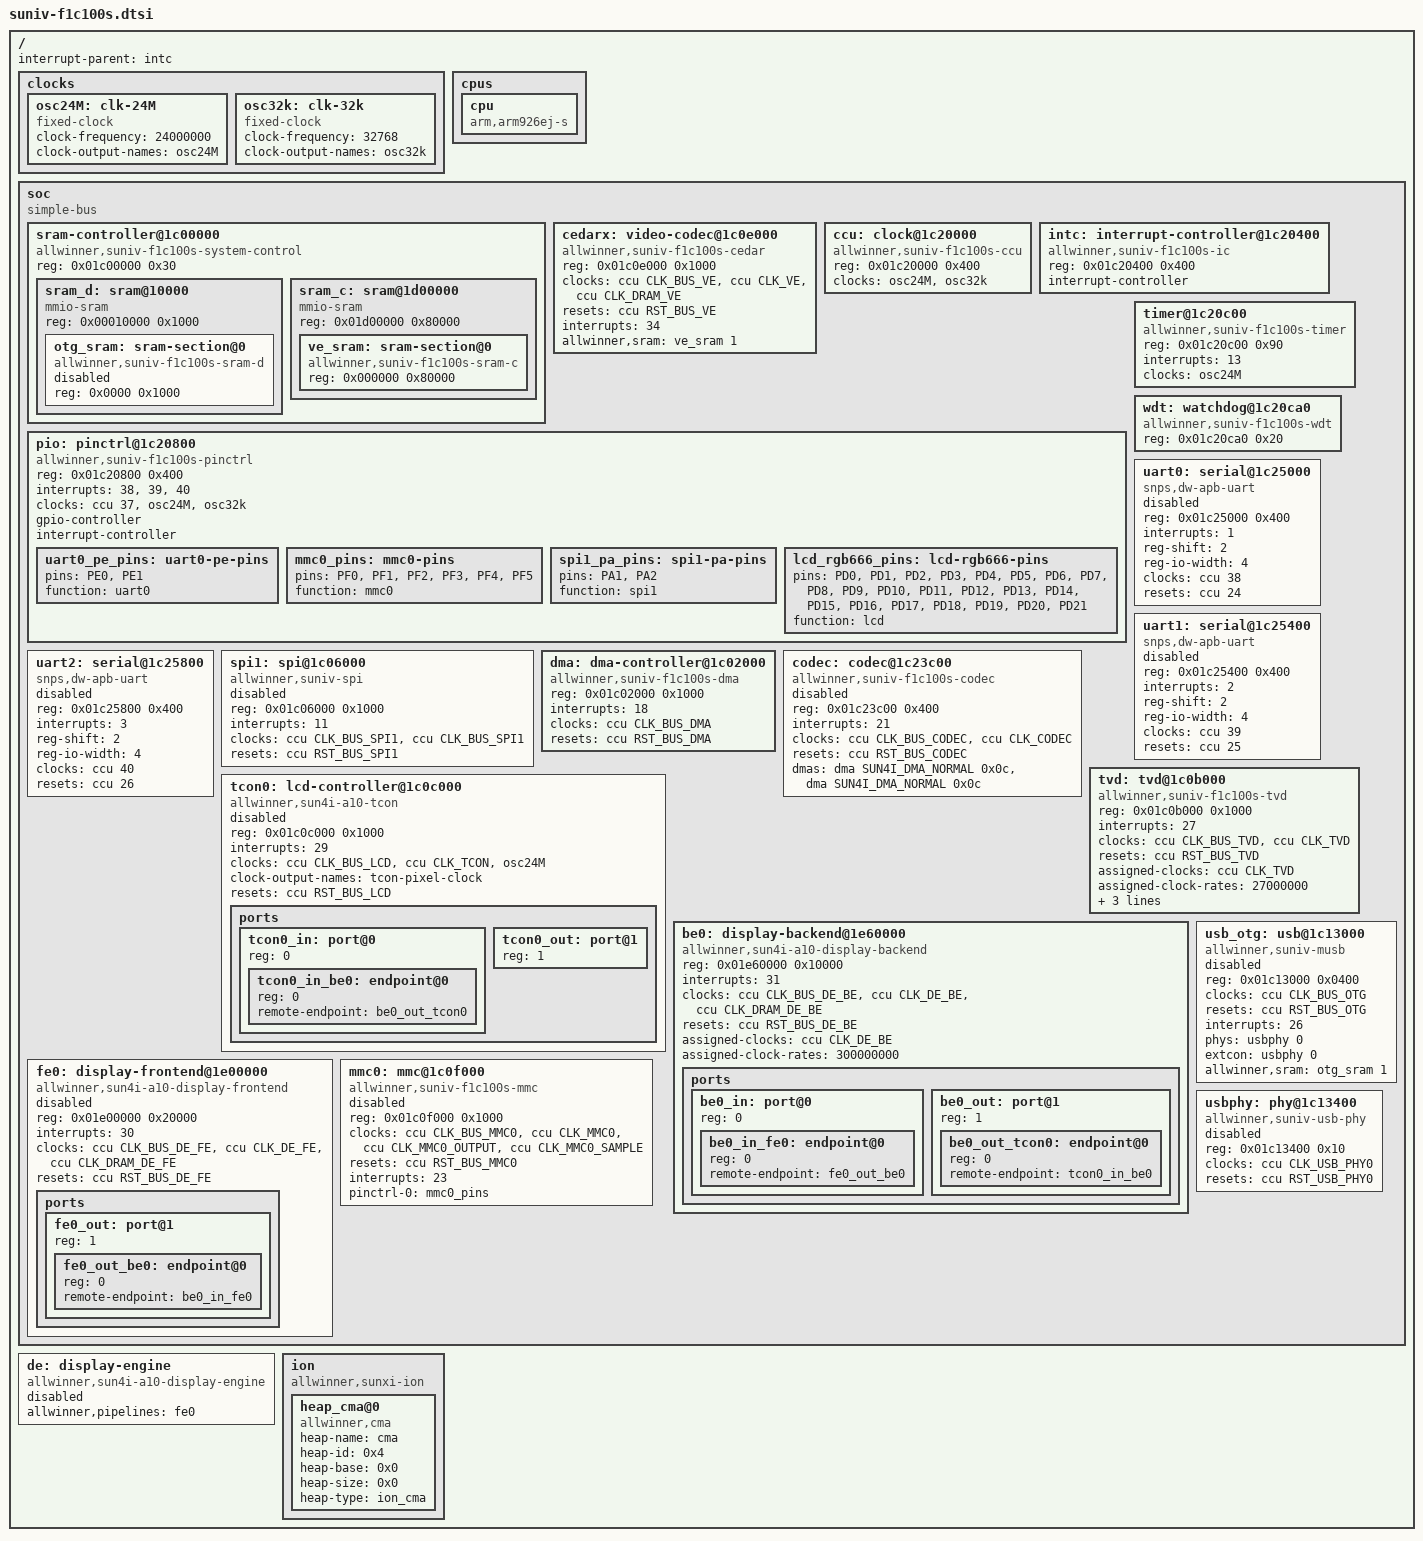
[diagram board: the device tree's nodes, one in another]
// SPDX-License-Identifier: (GPL-2.0+ OR X11)
/*
 * Copyright 2018 Icenowy Zheng <icenowy@aosc.io>
 * Copyright 2018 Mesih Kilinc <mesihkilinc@gmail.com>
 */
#include <dt-bindings/clock/suniv-ccu-f1c100s.h>
#include <dt-bindings/reset/suniv-ccu-f1c100s.h>
#include <dt-bindings/dma/sun4i-a10.h>


/ {
	#address-cells = <1>;
	#size-cells = <1>;
	interrupt-parent = <&intc>;

	clocks {
		osc24M: clk-24M {
			#clock-cells = <0>;
			compatible = "fixed-clock";
			clock-frequency = <24000000>;
			clock-output-names = "osc24M";
		};

		osc32k: clk-32k {
			#clock-cells = <0>;
			compatible = "fixed-clock";
			clock-frequency = <32768>;
			clock-output-names = "osc32k";
		};
	};

	cpus {
		cpu {
			compatible = "arm,arm926ej-s";
			device_type = "cpu";
		};
	};

	soc {
		compatible = "simple-bus";
		#address-cells = <1>;
		#size-cells = <1>;
		ranges;

  sram-controller@1c00000 {
      compatible = "allwinner,suniv-f1c100s-system-control",
                   "allwinner,sun4i-a10-system-control";
      reg = <0x01c00000 0x30>;
      #address-cells = <1>;
      #size-cells = <1>;
      ranges;

      sram_d: sram@10000 {
          compatible = "mmio-sram";
          reg = <0x00010000 0x1000>;
          #address-cells = <1>;
          #size-cells = <1>;
          ranges = <0 0x00010000 0x1000>;

          otg_sram: sram-section@0 {
              compatible = "allwinner,suniv-f1c100s-sram-d",
                           "allwinner,sun4i-a10-sram-d";
              reg = <0x0000 0x1000>;
              status = "disabled";
          };
      };

      sram_c: sram@1d00000 {
          compatible = "mmio-sram";
          reg = <0x01d00000 0x80000>;
          #address-cells = <1>;
          #size-cells = <1>;
          ranges = <0 0x01d00000 0x80000>;

          ve_sram: sram-section@0 {
              compatible = "allwinner,suniv-f1c100s-sram-c",
                           "allwinner,sun4i-a10-sram-c1";
              reg = <0x000000 0x80000>;
          };
      };
  };
  cedarx: video-codec@1c0e000 {
      compatible = "allwinner,suniv-f1c100s-cedar";
      reg = <0x01c0e000 0x1000>;
      clocks = <&ccu CLK_BUS_VE>, <&ccu CLK_VE>, <&ccu CLK_DRAM_VE>;
      clock-names = "ahb", "mod", "ram";
      resets = <&ccu RST_BUS_VE>;
      interrupts = <34>;
      allwinner,sram = <&ve_sram 1>;
      status = "okay";
  };

		ccu: clock@1c20000 {
			compatible = "allwinner,suniv-f1c100s-ccu";
			reg = <0x01c20000 0x400>;
			clocks = <&osc24M>, <&osc32k>;
			clock-names = "hosc", "losc";
			#clock-cells = <1>;
			#reset-cells = <1>;
		};

		intc: interrupt-controller@1c20400 {
			compatible = "allwinner,suniv-f1c100s-ic";
			reg = <0x01c20400 0x400>;
			interrupt-controller;
			#interrupt-cells = <1>;
		};

		pio: pinctrl@1c20800 {
			compatible = "allwinner,suniv-f1c100s-pinctrl";
			reg = <0x01c20800 0x400>;
			interrupts = <38>, <39>, <40>;
			clocks = <&ccu 37>, <&osc24M>, <&osc32k>;
			clock-names = "apb", "hosc", "losc";
			gpio-controller;
			interrupt-controller;
			#interrupt-cells = <3>;
			#gpio-cells = <3>;

			uart0_pe_pins: uart0-pe-pins {
				pins = "PE0", "PE1";
				function = "uart0";
			};
			mmc0_pins: mmc0-pins {
                		pins = "PF0", "PF1", "PF2", "PF3", "PF4", "PF5";
                		function = "mmc0";
            		};
spi1_pa_pins: spi1-pa-pins {
pins = "PA1", "PA2";
        function = "spi1";
            };
lcd_rgb666_pins: lcd-rgb666-pins {  //分号前是给节点起的别名，分号后是节点的名称。首先是申请RGB驱动的引脚
				pins = "PD0", "PD1", "PD2", "PD3", "PD4",
				       "PD5", "PD6", "PD7", "PD8", "PD9",
				       "PD10", "PD11", "PD12", "PD13", "PD14",
				       "PD15", "PD16", "PD17", "PD18", "PD19",
				       "PD20", "PD21";
				function = "lcd";
			};

		};

		timer@1c20c00 {
			compatible = "allwinner,suniv-f1c100s-timer";
			reg = <0x01c20c00 0x90>;
			interrupts = <13>;
			clocks = <&osc24M>;
		};

		wdt: watchdog@1c20ca0 {
			compatible = "allwinner,suniv-f1c100s-wdt",
				     "allwinner,sun4i-a10-wdt";
			reg = <0x01c20ca0 0x20>;
		};

		uart0: serial@1c25000 {
			compatible = "snps,dw-apb-uart";
			reg = <0x01c25000 0x400>;
			interrupts = <1>;
			reg-shift = <2>;
			reg-io-width = <4>;
			clocks = <&ccu 38>;
			resets = <&ccu 24>;
			status = "disabled";
		};

		uart1: serial@1c25400 {
			compatible = "snps,dw-apb-uart";
			reg = <0x01c25400 0x400>;
			interrupts = <2>;
			reg-shift = <2>;
			reg-io-width = <4>;
			clocks = <&ccu 39>;
			resets = <&ccu 25>;
			status = "disabled";
		};

		uart2: serial@1c25800 {
			compatible = "snps,dw-apb-uart";
			reg = <0x01c25800 0x400>;
			interrupts = <3>;
			reg-shift = <2>;
			reg-io-width = <4>;
			clocks = <&ccu 40>;
			resets = <&ccu 26>;
			status = "disabled";
		};
spi1: spi@1c06000 {
    compatible = "allwinner,suniv-spi",
                 "allwinner,sun8i-h3-spi";
    reg = <0x01c06000 0x1000>;
    interrupts = <11>;
    clocks = <&ccu CLK_BUS_SPI1>, <&ccu CLK_BUS_SPI1>;
    clock-names = "ahb", "mod";
    resets = <&ccu RST_BUS_SPI1>;
    status = "disabled";
    #address-cells = <1>;
    #size-cells = <0>;
};

dma: dma-controller@1c02000 {
    compatible = "allwinner,suniv-f1c100s-dma";
    reg = <0x01c02000 0x1000>;
    interrupts = <18>;
    clocks = <&ccu CLK_BUS_DMA>;
    resets = <&ccu RST_BUS_DMA>;
    #dma-cells = <2>;
};

codec: codec@1c23c00 {
    compatible = "allwinner,suniv-f1c100s-codec";
    reg = <0x01c23c00 0x400>;
    interrupts = <21>;
    clocks = <&ccu CLK_BUS_CODEC>,
         <&ccu CLK_CODEC>;
    clock-names = "apb", "codec";
    resets = <&ccu RST_BUS_CODEC>;
    dmas = <&dma SUN4I_DMA_NORMAL 0x0c>, 
         <&dma SUN4I_DMA_NORMAL 0x0c>;
    dma-names = "rx", "tx";
    status = "disabled";
};

  #include <dt-bindings/clock/suniv-ccu-f1c100s.h>
  #include <dt-bindings/reset/suniv-ccu-f1c100s.h>

  tvd: tvd@1c0b000 {
      compatible = "allwinner,suniv-f1c100s-tvd";
      reg = <0x01c0b000 0x1000>;
      interrupts = <27>;

      clocks = <&ccu CLK_BUS_TVD>,
               <&ccu CLK_TVD>;
      clock-names = "bus", "mod";

      resets = <&ccu RST_BUS_TVD>;
      reset-names = "bus";

      assigned-clocks = <&ccu CLK_TVD>;
      assigned-clock-rates = <27000000>;

      allwinner,input-channel = <0>;
      allwinner,default-standard = "ntsc";
      allwinner,blue-screen-mode = <2>;
      /* allwinner,auto-detect-standard; */

      status = "okay";
  };


tcon0: lcd-controller@1c0c000 {  //添加显示驱动的节点，即RGB驱动，@后面是设备的物理地址。
			compatible = "allwinner,sun4i-a10-tcon";  //linux5.7.1内，已经没有f1c200s的相关支持，但是实测使用a10型号的驱动依然可用
			reg = <0x01c0c000 0x1000>;  //寄存器地址
			interrupts = <29>;  //中断号，是根据f1c200s手册查询得到的
			clocks = <&ccu CLK_BUS_LCD>,  //这里引用了外部宏定义，所以要添加对应的头文件，默认已经添加过了
				 <&ccu CLK_TCON>,
				 <&osc24M>;	/* Still unknown */
			clock-names = "ahb",
				      "tcon-ch0",
				      "tcon-ch1";
			clock-output-names = "tcon-pixel-clock";
			resets = <&ccu RST_BUS_LCD>;  //指定复位单元
			reset-names = "lcd";  //复位单元名称？
			status = "disabled";  //先禁用设备

			ports {  //port是管道，或者说端口，设备间的数据通过管道传输。
				#address-cells = <1>;  //设置子节点的地址占用大小
				#size-cells = <0>;  //设置子节点寄存器尺寸描述占用大小

				tcon0_in: port@0 {  //port管道端口0是输入口
					#address-cells = <1>;
					#size-cells = <0>;
					reg = <0>;

					tcon0_in_be0: endpoint@0 {  //port管道端口0的对端口为be0_out_tcon0
						reg = <0>;
						remote-endpoint = <&be0_out_tcon0>;
					};
				};

				tcon0_out: port@1 {  //port管道端口1是输出口
					#address-cells = <1>;
					#size-cells = <0>;
					reg = <1>;
				};
			};
		};
		be0: display-backend@1e60000 {  //be0是显示后端处理，显示后端处理主要针对图片叠加
			compatible = "allwinner,sun4i-a10-display-backend";
			reg = <0x01e60000 0x10000>;
			reg-names = "be";
			interrupts = <31>;
			clocks = <&ccu CLK_BUS_DE_BE>, <&ccu CLK_DE_BE>,
				 <&ccu CLK_DRAM_DE_BE>;
			clock-names = "ahb", "mod",
				      "ram";
			resets = <&ccu RST_BUS_DE_BE>;
			reset-names = "be";
			assigned-clocks = <&ccu CLK_DE_BE>;
			assigned-clock-rates = <300000000>;

			ports {  //be0也是拥有两个端口
				#address-cells = <1>;
				#size-cells = <0>;

				be0_in: port@0 {  //be0管道端口0的对端是fe0_out_be0
					#address-cells = <1>;
					#size-cells = <0>;
					reg = <0>;

					be0_in_fe0: endpoint@0 {
						reg = <0>;
						remote-endpoint = <&fe0_out_be0>;
					};
				};

				be0_out: port@1 {  //be0管道端口1的对端是tcon0_in_be0
					#address-cells = <1>;
					#size-cells = <0>;
					reg = <1>;

					be0_out_tcon0: endpoint@0 {
						reg = <0>;
						remote-endpoint = <&tcon0_in_be0>;
					};
				};
			};
		};
		fe0: display-frontend@1e00000 {  //fe0是显示前端处理，显示前端主要针对图片的缩放。
			compatible = "allwinner,sun4i-a10-display-frontend";  //这里也是借用a10的驱动
			reg = <0x01e00000 0x20000>;
			interrupts = <30>;
			clocks = <&ccu CLK_BUS_DE_FE>, <&ccu CLK_DE_FE>,
				 <&ccu CLK_DRAM_DE_FE>;
			clock-names = "ahb", "mod",
				      "ram";
			resets = <&ccu RST_BUS_DE_FE>;
			status = "disabled";

			ports {
				#address-cells = <1>;
				#size-cells = <0>;

				fe0_out: port@1 {  //fe0管道端口1是输出口，其对端口为be0_in_fe0
					#address-cells = <1>;
					#size-cells = <0>;
					reg = <1>;

					fe0_out_be0: endpoint@0 {
						reg = <0>;
						remote-endpoint = <&be0_in_fe0>;
					};
				};
			};
		};

mmc0: mmc@1c0f000 {
            compatible = "allwinner,suniv-f1c100s-mmc",
                     "allwinner,sun7i-a20-mmc";
            reg = <0x01c0f000 0x1000>;
            clocks = <&ccu CLK_BUS_MMC0>,
                 <&ccu CLK_MMC0>,
                 <&ccu CLK_MMC0_OUTPUT>,
                 <&ccu CLK_MMC0_SAMPLE>;
            clock-names = "ahb",
                          "mmc",
                          "output",
                          "sample";
            resets = <&ccu RST_BUS_MMC0>;
            reset-names = "ahb";
            interrupts = <23>;
            pinctrl-names = "default";
            pinctrl-0 = <&mmc0_pins>;
            status = "disabled";
            #address-cells = <1>;
            #size-cells = <0>;
        };
usb_otg: usb@1c13000 {
    compatible = "allwinner,suniv-musb";
    reg = <0x01c13000 0x0400>;
    clocks = <&ccu CLK_BUS_OTG>;
    resets = <&ccu RST_BUS_OTG>;
    interrupts = <26>;
    interrupt-names = "mc";
    phys = <&usbphy 0>;
    phy-names = "usb";
    extcon = <&usbphy 0>;
    allwinner,sram = <&otg_sram 1>;
    status = "disabled";
};
usbphy: phy@1c13400 {
    compatible = "allwinner,suniv-usb-phy";
    reg = <0x01c13400 0x10>;
    reg-names = "phy_ctrl";
    clocks = <&ccu CLK_USB_PHY0>;
    clock-names = "usb0_phy";
    resets = <&ccu RST_USB_PHY0>;
    reset-names = "usb0_reset";
    #phy-cells = <1>;
    status = "disabled";
};
	};
	de: display-engine {
		compatible = "allwinner,sun4i-a10-display-engine";
		allwinner,pipelines = <&fe0>;
		status = "disabled";
	};
  ion: ion {
      compatible = "allwinner,sunxi-ion";
      status = "okay";

      heap_cma@0 {
          compatible = "allwinner,cma";
          heap-name = "cma";
          heap-id = <0x4>;
          heap-base = <0x0>;
          heap-size = <0x0>;
          heap-type = "ion_cma";
      };
  };
};
